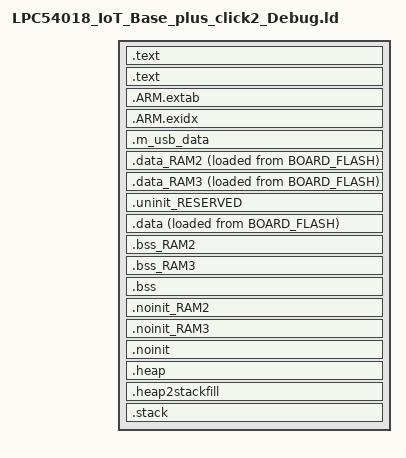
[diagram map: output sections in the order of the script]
/*
 * GENERATED FILE - DO NOT EDIT
 * (c) Code Red Technologies Ltd, 2008-2013
 * (c) NXP Semiconductors 2013-2018
 * Generated linker script file for LPC54018
 * Created from linkscript.ldt by FMCreateLinkLibraries
 * Using Freemarker v2.3.23
 * MCUXpresso IDE v10.2.0_prc2 [Build 737] [2018-04-12]  on May 15, 2018 12:14:59 PM
 */

INCLUDE "LPC54018_IoT_Base_plus_click2_Debug_library.ld"
INCLUDE "LPC54018_IoT_Base_plus_click2_Debug_memory.ld"

ENTRY(ResetISR)

SECTIONS
{
    /* MAIN TEXT SECTION */
    .text : ALIGN(4)
    {
        FILL(0xff)
        __vectors_start__ = ABSOLUTE(.) ;
        KEEP(*(.isr_vector))
        /* Global Section Table */
        . = ALIGN(4) ;
        __section_table_start = .;
        __data_section_table = .;
        LONG(LOADADDR(.data));
        LONG(    ADDR(.data));
        LONG(  SIZEOF(.data));
        LONG(LOADADDR(.data_RAM2));
        LONG(    ADDR(.data_RAM2));
        LONG(  SIZEOF(.data_RAM2));
        LONG(LOADADDR(.data_RAM3));
        LONG(    ADDR(.data_RAM3));
        LONG(  SIZEOF(.data_RAM3));
        __data_section_table_end = .;
        __bss_section_table = .;
        LONG(    ADDR(.bss));
        LONG(  SIZEOF(.bss));
        LONG(    ADDR(.bss_RAM2));
        LONG(  SIZEOF(.bss_RAM2));
        LONG(    ADDR(.bss_RAM3));
        LONG(  SIZEOF(.bss_RAM3));
        __bss_section_table_end = .;
        __section_table_end = . ;
        /* End of Global Section Table */

        *(.after_vectors*)

    } > BOARD_FLASH

    .text : ALIGN(4)
    {
       *(.text*)
       *(.rodata .rodata.* .constdata .constdata.*)
       . = ALIGN(4);
            /* C++ constructors etc */
            . = ALIGN(4);
            KEEP(*(.init))
            
            . = ALIGN(4);
            __preinit_array_start = .;
            KEEP (*(.preinit_array))
            __preinit_array_end = .;
            
            . = ALIGN(4);
            __init_array_start = .;
            KEEP (*(SORT(.init_array.*)))
            KEEP (*(.init_array))
            __init_array_end = .;
            
            KEEP(*(.fini));
            
            . = ALIGN(4);
            KEEP (*crtbegin.o(.ctors))
            KEEP (*(EXCLUDE_FILE (*crtend.o) .ctors))
            KEEP (*(SORT(.ctors.*)))
            KEEP (*crtend.o(.ctors))
            
            . = ALIGN(4);
            KEEP (*crtbegin.o(.dtors))
            KEEP (*(EXCLUDE_FILE (*crtend.o) .dtors))
            KEEP (*(SORT(.dtors.*)))
            KEEP (*crtend.o(.dtors))
            . = ALIGN(4);
            /* End C++ */
    } > BOARD_FLASH
    /*
     * for exception handling/unwind - some Newlib functions (in common
     * with C++ and STDC++) use this. 
     */
    .ARM.extab : ALIGN(4) 
    {
        *(.ARM.extab* .gnu.linkonce.armextab.*)
    } > BOARD_FLASH

    __exidx_start = .;

    .ARM.exidx : ALIGN(4)
    {
        *(.ARM.exidx* .gnu.linkonce.armexidx.*)
    } > BOARD_FLASH
    __exidx_end = .;

    _etext = .;
        
 
    /* USB_RAM */
    .m_usb_data (NOLOAD) :
    {
        *(m_usb_global)
    } > USB_RAM
    /* DATA section for SRAM_0_1_2_3 */

    .data_RAM2 : ALIGN(4)
    {
        FILL(0xff)
        PROVIDE(__start_data_RAM2 = .) ;
        *(.ramfunc.$RAM2)
        *(.ramfunc.$SRAM_0_1_2_3)
        *(.data.$RAM2*)
        *(.data.$SRAM_0_1_2_3*)
        . = ALIGN(4) ;
        PROVIDE(__end_data_RAM2 = .) ;
     } > SRAM_0_1_2_3 AT>BOARD_FLASH
    /* DATA section for USB_RAM */

    .data_RAM3 : ALIGN(4)
    {
        FILL(0xff)
        PROVIDE(__start_data_RAM3 = .) ;
        *(.ramfunc.$RAM3)
        *(.ramfunc.$USB_RAM)
        *(.data.$RAM3*)
        *(.data.$USB_RAM*)
        . = ALIGN(4) ;
        PROVIDE(__end_data_RAM3 = .) ;
     } > USB_RAM AT>BOARD_FLASH
    /* MAIN DATA SECTION */
    .uninit_RESERVED : ALIGN(4)
    {
        KEEP(*(.bss.$RESERVED*))
        . = ALIGN(4) ;
        _end_uninit_RESERVED = .;
    } > SRAMX

    /* Main DATA section (SRAMX) */
    .data : ALIGN(4)
    {
       FILL(0xff)
       _data = . ;
       *(vtable)
       *(.ramfunc*)
       *(.data*)
       . = ALIGN(4) ;
       _edata = . ;
    } > SRAMX AT>BOARD_FLASH

    /* BSS section for SRAM_0_1_2_3 */
    .bss_RAM2 : ALIGN(4)
    {
       PROVIDE(__start_bss_RAM2 = .) ;
       *(.bss.$RAM2*)
       *(.bss.$SRAM_0_1_2_3*)
       . = ALIGN (. != 0 ? 4 : 1) ; /* avoid empty segment */
       PROVIDE(__end_bss_RAM2 = .) ;
    } > SRAM_0_1_2_3 

    /* BSS section for USB_RAM */
    .bss_RAM3 : ALIGN(4)
    {
       PROVIDE(__start_bss_RAM3 = .) ;
       *(.bss.$RAM3*)
       *(.bss.$USB_RAM*)
       . = ALIGN (. != 0 ? 4 : 1) ; /* avoid empty segment */
       PROVIDE(__end_bss_RAM3 = .) ;
    } > USB_RAM 

    /* MAIN BSS SECTION */
    .bss : ALIGN(4)
    {
        _bss = .;
        *(.bss*)
        *(COMMON)
        . = ALIGN(4) ;
        _ebss = .;
        PROVIDE(end = .);
    } > SRAMX

    /* NOINIT section for SRAM_0_1_2_3 */
    .noinit_RAM2 (NOLOAD) : ALIGN(4)
    {
       *(.noinit.$RAM2*)
       *(.noinit.$SRAM_0_1_2_3*)
       . = ALIGN(4) ;
    } > SRAM_0_1_2_3 

    /* NOINIT section for USB_RAM */
    .noinit_RAM3 (NOLOAD) : ALIGN(4)
    {
       *(.noinit.$RAM3*)
       *(.noinit.$USB_RAM*)
       . = ALIGN(4) ;
    } > USB_RAM 

    /* DEFAULT NOINIT SECTION */
    .noinit (NOLOAD): ALIGN(4)
    {
        _noinit = .;
        *(.noinit*) 
         . = ALIGN(4) ;
        _end_noinit = .;
    } > SRAMX

    /* Reserve and place Heap within memory map */
    _HeapSize = 0x1000;
    .heap :  ALIGN(4)
    {
        _pvHeapStart = .;
        . += _HeapSize;
        . = ALIGN(4);
        _pvHeapLimit = .;
    } > SRAMX

     _StackSize = 0x1000;
     /* Reserve space in memory for Stack */
    .heap2stackfill  :
    {
        . += _StackSize;
    } > SRAMX
    /* Locate actual Stack in memory map */
    .stack ORIGIN(SRAMX) + LENGTH(SRAMX) - _StackSize - 0:  ALIGN(4)
    {
        _vStackBase = .;
        . = ALIGN(4);
        _vStackTop = . + _StackSize;
    } > SRAMX

    /* ## Create checksum value (used in startup) ## */
    PROVIDE(__valid_user_code_checksum = 0 - 
                                         (_vStackTop 
                                         + (ResetISR + 1) 
                                         + (NMI_Handler + 1) 
                                         + (HardFault_Handler + 1) 
                                         + (( DEFINED(MemManage_Handler) ? MemManage_Handler : 0 ) + 1)   /* MemManage_Handler may not be defined */
                                         + (( DEFINED(BusFault_Handler) ? BusFault_Handler : 0 ) + 1)     /* BusFault_Handler may not be defined */
                                         + (( DEFINED(UsageFault_Handler) ? UsageFault_Handler : 0 ) + 1) /* UsageFault_Handler may not be defined */
                                         ) );

    /* Provide basic symbols giving location and size of main text
     * block, including initial values of RW data sections. Note that
     * these will need extending to give a complete picture with
     * complex images (e.g multiple Flash banks).
     */
    _image_start = LOADADDR(.text);
    _image_end = LOADADDR(.data) + SIZEOF(.data);
    _image_size = _image_end - _image_start;

    /* Provide symbols for LPC540xx parts for startup code to use
     * to set image to be plain load image or XIP.
     * Config : Plain load image = false
     */
    __imghdr_loadaddress = LOADADDR(.text);
    __imghdr_imagetype = 3;
}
